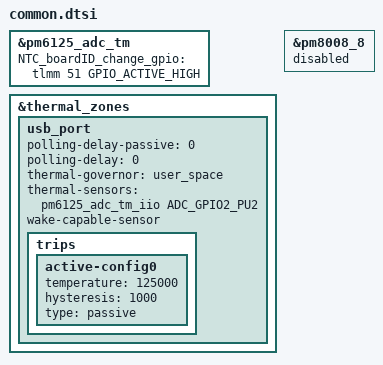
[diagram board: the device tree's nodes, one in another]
#include "../../common/common.dtsi"
#include "huawei-lcd.dtsi"
#include "huawei-tp.dtsi"
#include "huawei_charger_22p5W.dtsi"
#include "huawei_audio.dtsi"
#include "huawei-sensor.dtsi"
#include "huawei-camera.dtsi"
#include "huawei-bt.dtsi"
#include "huawei_fac.dtsi"
#include "huawei_fp.dtsi"

&pm6125_adc_tm {
	NTC_boardID_change_gpio = <&tlmm 51 GPIO_ACTIVE_HIGH>;
};

&thermal_zones {
	usb_port {
		polling-delay-passive = <0>;
		polling-delay = <0>;
		thermal-governor = "user_space";
		thermal-sensors = <&pm6125_adc_tm_iio ADC_GPIO2_PU2>;
		wake-capable-sensor;
		trips {
			active-config0 {
				temperature = <125000>;
				hysteresis = <1000>;
				type = "passive";
			};
		};
	};
};

&pm8008_8 {
	status = "disabled";
};
